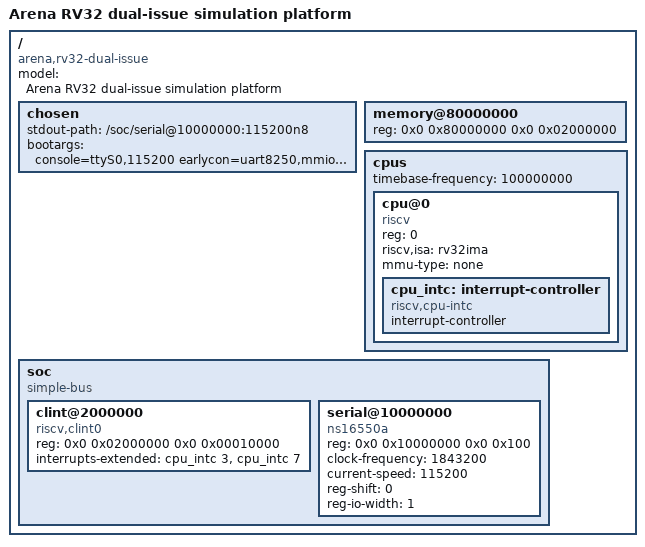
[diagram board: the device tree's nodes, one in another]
/dts-v1/;

/ {
    #address-cells = <2>;
    #size-cells = <2>;
    model = "Arena RV32 dual-issue simulation platform";
    compatible = "arena,rv32-dual-issue", "riscv-virtio";

    chosen {
        stdout-path = "/soc/serial@10000000:115200n8";
        bootargs = "console=ttyS0,115200 earlycon=uart8250,mmio,0x10000000,115200n8 loglevel=8";
    };

    memory@80000000 {
        device_type = "memory";
        reg = <0x0 0x80000000 0x0 0x02000000>;
    };

    cpus {
        #address-cells = <1>;
        #size-cells = <0>;
        timebase-frequency = <100000000>;

        cpu@0 {
            device_type = "cpu";
            compatible = "riscv";
            reg = <0>;
            status = "okay";
            riscv,isa = "rv32ima";
            mmu-type = "none";
            cpu_intc: interrupt-controller {
                #address-cells = <0>;
                #interrupt-cells = <1>;
                interrupt-controller;
                compatible = "riscv,cpu-intc";
            };
        };
    };

    soc {
        #address-cells = <2>;
        #size-cells = <2>;
        compatible = "simple-bus";
        ranges;

        clint@2000000 {
            compatible = "riscv,clint0";
            reg = <0x0 0x02000000 0x0 0x00010000>;
            interrupts-extended = <&cpu_intc 3 &cpu_intc 7>;
        };

        serial@10000000 {
            compatible = "ns16550a";
            reg = <0x0 0x10000000 0x0 0x100>;
            clock-frequency = <1843200>;
            current-speed = <115200>;
            reg-shift = <0>;
            reg-io-width = <1>;
            status = "okay";
        };
    };
};
